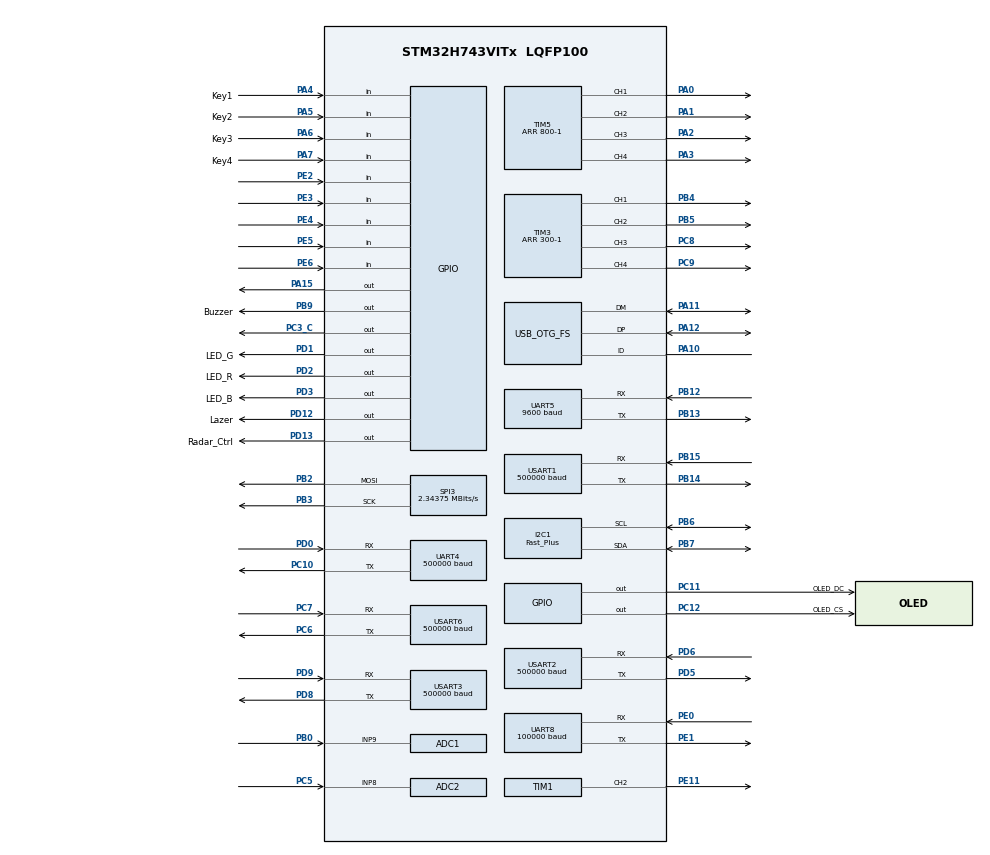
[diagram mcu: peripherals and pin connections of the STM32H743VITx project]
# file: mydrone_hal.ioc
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ADC1.Channel-3\#ChannelRegularConversion=ADC_CHANNEL_9
ADC1.ClockPrescaler=ADC_CLOCK_ASYNC_DIV4
ADC1.ContinuousConvMode=ENABLE
ADC1.ConversionDataManagement=ADC_CONVERSIONDATA_DMA_CIRCULAR
ADC1.NbrOfConversionFlag=1
ADC1.OffsetNumber-3\#ChannelRegularConversion=ADC_OFFSET_NONE
ADC1.OffsetSignedSaturation-3\#ChannelRegularConversion=DISABLE
ADC1.Overrun=ADC_OVR_DATA_OVERWRITTEN
ADC1.Rank-3\#ChannelRegularConversion=1
ADC1.Resolution=ADC_RESOLUTION_16B
ADC1.SamplingTime-3\#ChannelRegularConversion=ADC_SAMPLETIME_810CYCLES_5
ADC1.master=1
ADC2.Channel-1\#ChannelRegularConversion=ADC_CHANNEL_8
ADC2.ClockPrescaler=ADC_CLOCK_ASYNC_DIV4
ADC2.ContinuousConvMode=ENABLE
ADC2.ConversionDataManagement=ADC_CONVERSIONDATA_DMA_CIRCULAR
ADC2.NbrOfConversionFlag=1
ADC2.OffsetNumber-1\#ChannelRegularConversion=ADC_OFFSET_NONE
ADC2.OffsetSignedSaturation-1\#ChannelRegularConversion=DISABLE
ADC2.Overrun=ADC_OVR_DATA_OVERWRITTEN
ADC2.Rank-1\#ChannelRegularConversion=1
ADC2.Resolution=ADC_RESOLUTION_16B
ADC2.SamplingTime-1\#ChannelRegularConversion=ADC_SAMPLETIME_810CYCLES_5
CORTEX_M7.AccessPermission_S-Cortex_Memory_Protection_Unit_Region1_Settings_S=MPU_REGION_FULL_ACCESS
CORTEX_M7.AccessPermission_Spec=MPU_REGION_FULL_ACCESS
CORTEX_M7.BaseAddress_S-Cortex_Memory_Protection_Unit_Region1_Settings_S=0x24000000
CORTEX_M7.BaseAddress_Spec=0x24000000
CORTEX_M7.CPU_DCache=Enabled
CORTEX_M7.CPU_ICache=Enabled
CORTEX_M7.DisableExec_S-Cortex_Memory_Protection_Unit_Region1_Settings_S=MPU_INSTRUCTION_ACCESS_DISABLE
CORTEX_M7.DisableExec_Spec=MPU_INSTRUCTION_ACCESS_DISABLE
CORTEX_M7.Enable_S-Cortex_Memory_Protection_Unit_Region1_Settings_S=MPU_REGION_ENABLE
CORTEX_M7.Enable_Spec=MPU_REGION_ENABLE
CORTEX_M7.IsBufferable_S-Cortex_Memory_Protection_Unit_Region1_Settings_S=MPU_ACCESS_BUFFERABLE
CORTEX_M7.IsBufferable_Spec=MPU_ACCESS_NOT_BUFFERABLE
CORTEX_M7.IsCacheable_S-Cortex_Memory_Protection_Unit_Region1_Settings_S=MPU_ACCESS_CACHEABLE
CORTEX_M7.IsCacheable_Spec=MPU_ACCESS_NOT_CACHEABLE
CORTEX_M7.IsShareable_Spec=MPU_ACCESS_NOT_SHAREABLE
CORTEX_M7.Size_S-Cortex_Memory_Protection_Unit_Region1_Settings_S=MPU_REGION_SIZE_512KB
CORTEX_M7.Size_Spec=MPU_REGION_SIZE_4KB
CORTEX_M7.SubRegionDisable_S-Cortex_Memory_Protection_Unit_Region1_Settings_S=0x01
CORTEX_M7.SubRegionDisable_Spec=0x00
CORTEX_M7.TypeExtField_S-Cortex_Memory_Protection_Unit_Region1_Settings_S=MPU_TEX_LEVEL1
CORTEX_M7.TypeExtField_Spec=MPU_TEX_LEVEL1
CORTEX_M7.default_mode_Activation=1
Dma.ADC1.8.Direction=DMA_PERIPH_TO_MEMORY
Dma.ADC1.8.EventEnable=DISABLE
Dma.ADC1.8.FIFOMode=DMA_FIFOMODE_DISABLE
Dma.ADC1.8.Instance=DMA2_Stream2
Dma.ADC1.8.MemDataAlignment=DMA_MDATAALIGN_HALFWORD
Dma.ADC1.8.MemInc=DMA_MINC_ENABLE
Dma.ADC1.8.Mode=DMA_CIRCULAR
Dma.ADC1.8.PeriphDataAlignment=DMA_PDATAALIGN_HALFWORD
Dma.ADC1.8.PeriphInc=DMA_PINC_DISABLE
Dma.ADC1.8.Polarity=HAL_DMAMUX_REQ_GEN_RISING
Dma.ADC1.8.Priority=DMA_PRIORITY_LOW
Dma.ADC1.8.RequestNumber=1
Dma.ADC1.8.SignalID=NONE
Dma.ADC1.8.SyncEnable=DISABLE
Dma.ADC1.8.SyncPolarity=HAL_DMAMUX_SYNC_NO_EVENT
Dma.ADC1.8.SyncRequestNumber=1
Dma.ADC1.8.SyncSignalID=NONE
Dma.ADC2.6.Direction=DMA_PERIPH_TO_MEMORY
Dma.ADC2.6.EventEnable=DISABLE
Dma.ADC2.6.FIFOMode=DMA_FIFOMODE_DISABLE
Dma.ADC2.6.Instance=DMA2_Stream1
Dma.ADC2.6.MemDataAlignment=DMA_MDATAALIGN_HALFWORD
Dma.ADC2.6.MemInc=DMA_MINC_ENABLE
Dma.ADC2.6.Mode=DMA_CIRCULAR
Dma.ADC2.6.PeriphDataAlignment=DMA_PDATAALIGN_HALFWORD
Dma.ADC2.6.PeriphInc=DMA_PINC_DISABLE
Dma.ADC2.6.Polarity=HAL_DMAMUX_REQ_GEN_RISING
Dma.ADC2.6.Priority=DMA_PRIORITY_LOW
Dma.ADC2.6.RequestNumber=1
Dma.ADC2.6.SignalID=NONE
Dma.ADC2.6.SyncEnable=DISABLE
Dma.ADC2.6.SyncPolarity=HAL_DMAMUX_SYNC_NO_EVENT
Dma.ADC2.6.SyncRequestNumber=1
Dma.ADC2.6.SyncSignalID=NONE
Dma.Request0=UART4_TX
Dma.Request1=UART4_RX
Dma.Request10=TIM3_CH2
Dma.Request11=TIM3_CH3
Dma.Request12=TIM3_CH4
Dma.Request13=USART6_TX
Dma.Request14=USART3_RX
Dma.Request15=USART1_TX
Dma.Request2=TIM5_CH1
Dma.Request3=TIM5_CH2
Dma.Request4=TIM5_CH3
Dma.Request5=TIM5_CH4
Dma.Request6=ADC2
Dma.Request7=USART2_RX
Dma.Request8=ADC1
Dma.Request9=TIM3_CH1
Dma.TIM3_CH1.9.Direction=DMA_MEMORY_TO_PERIPH
Dma.TIM3_CH1.9.EventEnable=DISABLE
Dma.TIM3_CH1.9.FIFOMode=DMA_FIFOMODE_DISABLE
Dma.TIM3_CH1.9.Instance=DMA2_Stream3
Dma.TIM3_CH1.9.MemDataAlignment=DMA_MDATAALIGN_HALFWORD
Dma.TIM3_CH1.9.MemInc=DMA_MINC_ENABLE
Dma.TIM3_CH1.9.Mode=DMA_NORMAL
Dma.TIM3_CH1.9.PeriphDataAlignment=DMA_PDATAALIGN_HALFWORD
Dma.TIM3_CH1.9.PeriphInc=DMA_PINC_DISABLE
Dma.TIM3_CH1.9.Polarity=HAL_DMAMUX_REQ_GEN_RISING
Dma.TIM3_CH1.9.Priority=DMA_PRIORITY_LOW
Dma.TIM3_CH1.9.RequestNumber=1
Dma.TIM3_CH1.9.SignalID=NONE
Dma.TIM3_CH1.9.SyncEnable=DISABLE
Dma.TIM3_CH1.9.SyncPolarity=HAL_DMAMUX_SYNC_NO_EVENT
Dma.TIM3_CH1.9.SyncRequestNumber=1
Dma.TIM3_CH1.9.SyncSignalID=NONE
Dma.TIM3_CH2.10.Direction=DMA_MEMORY_TO_PERIPH
Dma.TIM3_CH2.10.EventEnable=DISABLE
Dma.TIM3_CH2.10.FIFOMode=DMA_FIFOMODE_DISABLE
Dma.TIM3_CH2.10.Instance=DMA2_Stream4
Dma.TIM3_CH2.10.MemDataAlignment=DMA_MDATAALIGN_HALFWORD
Dma.TIM3_CH2.10.MemInc=DMA_MINC_ENABLE
Dma.TIM3_CH2.10.Mode=DMA_NORMAL
Dma.TIM3_CH2.10.PeriphDataAlignment=DMA_PDATAALIGN_HALFWORD
Dma.TIM3_CH2.10.PeriphInc=DMA_PINC_DISABLE
Dma.TIM3_CH2.10.Polarity=HAL_DMAMUX_REQ_GEN_RISING
Dma.TIM3_CH2.10.Priority=DMA_PRIORITY_LOW
Dma.TIM3_CH2.10.RequestNumber=1
Dma.TIM3_CH2.10.SignalID=NONE
Dma.TIM3_CH2.10.SyncEnable=DISABLE
Dma.TIM3_CH2.10.SyncPolarity=HAL_DMAMUX_SYNC_NO_EVENT
Dma.TIM3_CH2.10.SyncRequestNumber=1
Dma.TIM3_CH2.10.SyncSignalID=NONE
Dma.TIM3_CH3.11.Direction=DMA_MEMORY_TO_PERIPH
Dma.TIM3_CH3.11.EventEnable=DISABLE
Dma.TIM3_CH3.11.FIFOMode=DMA_FIFOMODE_DISABLE
Dma.TIM3_CH3.11.Instance=DMA2_Stream6
Dma.TIM3_CH3.11.MemDataAlignment=DMA_MDATAALIGN_HALFWORD
Dma.TIM3_CH3.11.MemInc=DMA_MINC_ENABLE
Dma.TIM3_CH3.11.Mode=DMA_NORMAL
Dma.TIM3_CH3.11.PeriphDataAlignment=DMA_PDATAALIGN_HALFWORD
Dma.TIM3_CH3.11.PeriphInc=DMA_PINC_DISABLE
Dma.TIM3_CH3.11.Polarity=HAL_DMAMUX_REQ_GEN_RISING
Dma.TIM3_CH3.11.Priority=DMA_PRIORITY_LOW
Dma.TIM3_CH3.11.RequestNumber=1
Dma.TIM3_CH3.11.SignalID=NONE
Dma.TIM3_CH3.11.SyncEnable=DISABLE
Dma.TIM3_CH3.11.SyncPolarity=HAL_DMAMUX_SYNC_NO_EVENT
Dma.TIM3_CH3.11.SyncRequestNumber=1
Dma.TIM3_CH3.11.SyncSignalID=NONE
Dma.TIM3_CH4.12.Direction=DMA_MEMORY_TO_PERIPH
Dma.TIM3_CH4.12.EventEnable=DISABLE
Dma.TIM3_CH4.12.FIFOMode=DMA_FIFOMODE_DISABLE
Dma.TIM3_CH4.12.Instance=DMA2_Stream7
Dma.TIM3_CH4.12.MemDataAlignment=DMA_MDATAALIGN_HALFWORD
Dma.TIM3_CH4.12.MemInc=DMA_MINC_ENABLE
Dma.TIM3_CH4.12.Mode=DMA_NORMAL
Dma.TIM3_CH4.12.PeriphDataAlignment=DMA_PDATAALIGN_HALFWORD
Dma.TIM3_CH4.12.PeriphInc=DMA_PINC_DISABLE
Dma.TIM3_CH4.12.Polarity=HAL_DMAMUX_REQ_GEN_RISING
Dma.TIM3_CH4.12.Priority=DMA_PRIORITY_LOW
Dma.TIM3_CH4.12.RequestNumber=1
Dma.TIM3_CH4.12.SignalID=NONE
Dma.TIM3_CH4.12.SyncEnable=DISABLE
Dma.TIM3_CH4.12.SyncPolarity=HAL_DMAMUX_SYNC_NO_EVENT
Dma.TIM3_CH4.12.SyncRequestNumber=1
Dma.TIM3_CH4.12.SyncSignalID=NONE
Dma.TIM5_CH1.2.Direction=DMA_MEMORY_TO_PERIPH
Dma.TIM5_CH1.2.EventEnable=DISABLE
Dma.TIM5_CH1.2.FIFOMode=DMA_FIFOMODE_DISABLE
Dma.TIM5_CH1.2.Instance=DMA1_Stream5
Dma.TIM5_CH1.2.MemDataAlignment=DMA_MDATAALIGN_WORD
Dma.TIM5_CH1.2.MemInc=DMA_MINC_ENABLE
Dma.TIM5_CH1.2.Mode=DMA_NORMAL
Dma.TIM5_CH1.2.PeriphDataAlignment=DMA_PDATAALIGN_WORD
Dma.TIM5_CH1.2.PeriphInc=DMA_PINC_DISABLE
Dma.TIM5_CH1.2.Polarity=HAL_DMAMUX_REQ_GEN_RISING
Dma.TIM5_CH1.2.Priority=DMA_PRIORITY_HIGH
Dma.TIM5_CH1.2.RequestNumber=1
Dma.TIM5_CH1.2.SignalID=NONE
Dma.TIM5_CH1.2.SyncEnable=DISABLE
Dma.TIM5_CH1.2.SyncPolarity=HAL_DMAMUX_SYNC_NO_EVENT
Dma.TIM5_CH1.2.SyncRequestNumber=1
Dma.TIM5_CH1.2.SyncSignalID=NONE
Dma.TIM5_CH2.3.Direction=DMA_MEMORY_TO_PERIPH
Dma.TIM5_CH2.3.EventEnable=DISABLE
Dma.TIM5_CH2.3.FIFOMode=DMA_FIFOMODE_DISABLE
Dma.TIM5_CH2.3.Instance=DMA1_Stream6
Dma.TIM5_CH2.3.MemDataAlignment=DMA_MDATAALIGN_WORD
Dma.TIM5_CH2.3.MemInc=DMA_MINC_ENABLE
Dma.TIM5_CH2.3.Mode=DMA_NORMAL
Dma.TIM5_CH2.3.PeriphDataAlignment=DMA_PDATAALIGN_WORD
Dma.TIM5_CH2.3.PeriphInc=DMA_PINC_DISABLE
Dma.TIM5_CH2.3.Polarity=HAL_DMAMUX_REQ_GEN_RISING
Dma.TIM5_CH2.3.Priority=DMA_PRIORITY_HIGH
Dma.TIM5_CH2.3.RequestNumber=1
Dma.TIM5_CH2.3.SignalID=NONE
Dma.TIM5_CH2.3.SyncEnable=DISABLE
Dma.TIM5_CH2.3.SyncPolarity=HAL_DMAMUX_SYNC_NO_EVENT
Dma.TIM5_CH2.3.SyncRequestNumber=1
Dma.TIM5_CH2.3.SyncSignalID=NONE
Dma.TIM5_CH3.4.Direction=DMA_MEMORY_TO_PERIPH
Dma.TIM5_CH3.4.EventEnable=DISABLE
Dma.TIM5_CH3.4.FIFOMode=DMA_FIFOMODE_DISABLE
Dma.TIM5_CH3.4.Instance=DMA1_Stream7
Dma.TIM5_CH3.4.MemDataAlignment=DMA_MDATAALIGN_WORD
Dma.TIM5_CH3.4.MemInc=DMA_MINC_ENABLE
Dma.TIM5_CH3.4.Mode=DMA_NORMAL
Dma.TIM5_CH3.4.PeriphDataAlignment=DMA_PDATAALIGN_WORD
Dma.TIM5_CH3.4.PeriphInc=DMA_PINC_DISABLE
Dma.TIM5_CH3.4.Polarity=HAL_DMAMUX_REQ_GEN_RISING
Dma.TIM5_CH3.4.Priority=DMA_PRIORITY_HIGH
Dma.TIM5_CH3.4.RequestNumber=1
Dma.TIM5_CH3.4.SignalID=NONE
Dma.TIM5_CH3.4.SyncEnable=DISABLE
Dma.TIM5_CH3.4.SyncPolarity=HAL_DMAMUX_SYNC_NO_EVENT
Dma.TIM5_CH3.4.SyncRequestNumber=1
Dma.TIM5_CH3.4.SyncSignalID=NONE
Dma.TIM5_CH4.5.Direction=DMA_MEMORY_TO_PERIPH
Dma.TIM5_CH4.5.EventEnable=DISABLE
Dma.TIM5_CH4.5.FIFOMode=DMA_FIFOMODE_DISABLE
Dma.TIM5_CH4.5.Instance=DMA2_Stream0
Dma.TIM5_CH4.5.MemDataAlignment=DMA_MDATAALIGN_WORD
Dma.TIM5_CH4.5.MemInc=DMA_MINC_ENABLE
Dma.TIM5_CH4.5.Mode=DMA_NORMAL
Dma.TIM5_CH4.5.PeriphDataAlignment=DMA_PDATAALIGN_WORD
Dma.TIM5_CH4.5.PeriphInc=DMA_PINC_DISABLE
Dma.TIM5_CH4.5.Polarity=HAL_DMAMUX_REQ_GEN_RISING
Dma.TIM5_CH4.5.Priority=DMA_PRIORITY_HIGH
Dma.TIM5_CH4.5.RequestNumber=1
Dma.TIM5_CH4.5.SignalID=NONE
Dma.TIM5_CH4.5.SyncEnable=DISABLE
Dma.TIM5_CH4.5.SyncPolarity=HAL_DMAMUX_SYNC_NO_EVENT
Dma.TIM5_CH4.5.SyncRequestNumber=1
Dma.TIM5_CH4.5.SyncSignalID=NONE
Dma.UART4_RX.1.Direction=DMA_PERIPH_TO_MEMORY
Dma.UART4_RX.1.EventEnable=DISABLE
Dma.UART4_RX.1.FIFOMode=DMA_FIFOMODE_DISABLE
Dma.UART4_RX.1.Instance=DMA1_Stream1
Dma.UART4_RX.1.MemDataAlignment=DMA_MDATAALIGN_BYTE
Dma.UART4_RX.1.MemInc=DMA_MINC_ENABLE
Dma.UART4_RX.1.Mode=DMA_CIRCULAR
Dma.UART4_RX.1.PeriphDataAlignment=DMA_PDATAALIGN_BYTE
Dma.UART4_RX.1.PeriphInc=DMA_PINC_DISABLE
Dma.UART4_RX.1.Polarity=HAL_DMAMUX_REQ_GEN_RISING
Dma.UART4_RX.1.Priority=DMA_PRIORITY_LOW
Dma.UART4_RX.1.RequestNumber=1
Dma.UART4_RX.1.SignalID=NONE
Dma.UART4_RX.1.SyncEnable=DISABLE
Dma.UART4_RX.1.SyncPolarity=HAL_DMAMUX_SYNC_NO_EVENT
Dma.UART4_RX.1.SyncRequestNumber=1
Dma.UART4_RX.1.SyncSignalID=NONE
Dma.UART4_TX.0.Direction=DMA_MEMORY_TO_PERIPH
Dma.UART4_TX.0.EventEnable=DISABLE
Dma.UART4_TX.0.FIFOMode=DMA_FIFOMODE_DISABLE
Dma.UART4_TX.0.Instance=DMA1_Stream0
Dma.UART4_TX.0.MemDataAlignment=DMA_MDATAALIGN_BYTE
Dma.UART4_TX.0.MemInc=DMA_MINC_ENABLE
Dma.UART4_TX.0.Mode=DMA_NORMAL
Dma.UART4_TX.0.PeriphDataAlignment=DMA_PDATAALIGN_BYTE
Dma.UART4_TX.0.PeriphInc=DMA_PINC_DISABLE
Dma.UART4_TX.0.Polarity=HAL_DMAMUX_REQ_GEN_RISING
Dma.UART4_TX.0.Priority=DMA_PRIORITY_LOW
Dma.UART4_TX.0.RequestNumber=1
Dma.UART4_TX.0.SignalID=NONE
Dma.UART4_TX.0.SyncEnable=DISABLE
Dma.UART4_TX.0.SyncPolarity=HAL_DMAMUX_SYNC_NO_EVENT
Dma.UART4_TX.0.SyncRequestNumber=1
Dma.UART4_TX.0.SyncSignalID=NONE
Dma.USART1_TX.15.Direction=DMA_MEMORY_TO_PERIPH
Dma.USART1_TX.15.EventEnable=DISABLE
Dma.USART1_TX.15.FIFOMode=DMA_FIFOMODE_DISABLE
Dma.USART1_TX.15.Instance=DMA1_Stream3
Dma.USART1_TX.15.MemDataAlignment=DMA_MDATAALIGN_BYTE
Dma.USART1_TX.15.MemInc=DMA_MINC_ENABLE
Dma.USART1_TX.15.Mode=DMA_NORMAL
Dma.USART1_TX.15.PeriphDataAlignment=DMA_PDATAALIGN_BYTE
Dma.USART1_TX.15.PeriphInc=DMA_PINC_DISABLE
Dma.USART1_TX.15.Polarity=HAL_DMAMUX_REQ_GEN_RISING
Dma.USART1_TX.15.Priority=DMA_PRIORITY_LOW
Dma.USART1_TX.15.RequestNumber=1
Dma.USART1_TX.15.SignalID=NONE
Dma.USART1_TX.15.SyncEnable=DISABLE
Dma.USART1_TX.15.SyncPolarity=HAL_DMAMUX_SYNC_NO_EVENT
Dma.USART1_TX.15.SyncRequestNumber=1
Dma.USART1_TX.15.SyncSignalID=NONE
Dma.USART2_RX.7.Direction=DMA_PERIPH_TO_MEMORY
Dma.USART2_RX.7.EventEnable=DISABLE
Dma.USART2_RX.7.FIFOMode=DMA_FIFOMODE_DISABLE
Dma.USART2_RX.7.Instance=DMA1_Stream2
Dma.USART2_RX.7.MemDataAlignment=DMA_MDATAALIGN_BYTE
Dma.USART2_RX.7.MemInc=DMA_MINC_ENABLE
Dma.USART2_RX.7.Mode=DMA_CIRCULAR
Dma.USART2_RX.7.PeriphDataAlignment=DMA_PDATAALIGN_BYTE
Dma.USART2_RX.7.PeriphInc=DMA_PINC_DISABLE
Dma.USART2_RX.7.Polarity=HAL_DMAMUX_REQ_GEN_RISING
Dma.USART2_RX.7.Priority=DMA_PRIORITY_LOW
Dma.USART2_RX.7.RequestNumber=1
Dma.USART2_RX.7.SignalID=NONE
Dma.USART2_RX.7.SyncEnable=DISABLE
Dma.USART2_RX.7.SyncPolarity=HAL_DMAMUX_SYNC_NO_EVENT
Dma.USART2_RX.7.SyncRequestNumber=1
Dma.USART2_RX.7.SyncSignalID=NONE
Dma.USART3_RX.14.Direction=DMA_PERIPH_TO_MEMORY
Dma.USART3_RX.14.EventEnable=DISABLE
Dma.USART3_RX.14.FIFOMode=DMA_FIFOMODE_DISABLE
Dma.USART3_RX.14.Instance=DMA2_Stream5
Dma.USART3_RX.14.MemDataAlignment=DMA_MDATAALIGN_BYTE
Dma.USART3_RX.14.MemInc=DMA_MINC_ENABLE
Dma.USART3_RX.14.Mode=DMA_CIRCULAR
Dma.USART3_RX.14.PeriphDataAlignment=DMA_PDATAALIGN_BYTE
Dma.USART3_RX.14.PeriphInc=DMA_PINC_DISABLE
Dma.USART3_RX.14.Polarity=HAL_DMAMUX_REQ_GEN_RISING
Dma.USART3_RX.14.Priority=DMA_PRIORITY_LOW
Dma.USART3_RX.14.RequestNumber=1
Dma.USART3_RX.14.SignalID=NONE
Dma.USART3_RX.14.SyncEnable=DISABLE
Dma.USART3_RX.14.SyncPolarity=HAL_DMAMUX_SYNC_NO_EVENT
Dma.USART3_RX.14.SyncRequestNumber=1
Dma.USART3_RX.14.SyncSignalID=NONE
Dma.USART6_TX.13.Direction=DMA_MEMORY_TO_PERIPH
Dma.USART6_TX.13.EventEnable=DISABLE
Dma.USART6_TX.13.FIFOMode=DMA_FIFOMODE_DISABLE
Dma.USART6_TX.13.Instance=DMA1_Stream4
Dma.USART6_TX.13.MemDataAlignment=DMA_MDATAALIGN_BYTE
Dma.USART6_TX.13.MemInc=DMA_MINC_ENABLE
Dma.USART6_TX.13.Mode=DMA_NORMAL
Dma.USART6_TX.13.PeriphDataAlignment=DMA_PDATAALIGN_BYTE
Dma.USART6_TX.13.PeriphInc=DMA_PINC_DISABLE
Dma.USART6_TX.13.Polarity=HAL_DMAMUX_REQ_GEN_RISING
Dma.USART6_TX.13.Priority=DMA_PRIORITY_LOW
Dma.USART6_TX.13.RequestNumber=1
Dma.USART6_TX.13.SignalID=NONE
Dma.USART6_TX.13.SyncEnable=DISABLE
Dma.USART6_TX.13.SyncPolarity=HAL_DMAMUX_SYNC_NO_EVENT
Dma.USART6_TX.13.SyncRequestNumber=1
Dma.USART6_TX.13.SyncSignalID=NONE
FREERTOS.Tasks01=task_1ms_name,40,1024,task_1ms,As weak,NULL,Dynamic,NULL,NULL;task_tx_event,32,512,task_tx,As weak,NULL,Dynamic,NULL,NULL;task_rx_event,32,512,task_rx,As weak,NULL,Dynamic,NULL,NULL;task_ano_send_e,30,512,task_ano_send,As weak,NULL,Dynamic,NULL,NULL;task_event_name,31,256,task_event,As weak,NULL,Dynamic,NULL,NULL;task_timer_even,33,128,task_timer_event,As weak,NULL,Dynamic,NULL,NULL;task_10ms_name,29,512,task_10ms,As weak,NULL,Dynamic,NULL,NULL
FREERTOS.configENABLE_FPU=0
FREERTOS.configGENERATE_RUN_TIME_STATS=1
FREERTOS.configTOTAL_HEAP_SIZE=32768
FREERTOS.configUSE_STATS_FORMATTING_FUNCTIONS=1
I2C1.I2C_Speed_Mode=I2C_Fast_Plus
I2C1.Timing=0x0050174F
Mcu.Family=STM32H7
Mcu.Name=STM32H743VITx
Mcu.Package=LQFP100
NVIC.DMA1_Stream0_IRQn=true\:5\:0\:false\:false\:true\:true\:false\:true\:true
NVIC.DMA1_Stream1_IRQn=true\:5\:0\:false\:false\:true\:true\:false\:true\:true
NVIC.DMA1_Stream2_IRQn=true\:5\:0\:false\:false\:true\:true\:false\:true\:true
NVIC.DMA1_Stream3_IRQn=true\:5\:0\:false\:false\:true\:true\:false\:true\:true
NVIC.DMA1_Stream4_IRQn=true\:5\:0\:false\:false\:true\:true\:false\:true\:true
NVIC.DMA1_Stream5_IRQn=true\:5\:0\:false\:false\:true\:true\:false\:true\:true
NVIC.DMA1_Stream6_IRQn=true\:5\:0\:false\:false\:true\:true\:false\:true\:true
NVIC.DMA1_Stream7_IRQn=true\:5\:0\:false\:false\:true\:true\:false\:true\:true
NVIC.DMA2_Stream0_IRQn=true\:5\:0\:false\:false\:true\:true\:false\:true\:true
NVIC.DMA2_Stream1_IRQn=true\:5\:0\:false\:false\:true\:true\:false\:true\:true
NVIC.DMA2_Stream2_IRQn=true\:5\:0\:false\:false\:true\:true\:false\:true\:true
NVIC.DMA2_Stream3_IRQn=true\:5\:0\:false\:false\:true\:true\:false\:true\:true
NVIC.DMA2_Stream4_IRQn=true\:5\:0\:false\:false\:true\:true\:false\:true\:true
NVIC.DMA2_Stream5_IRQn=true\:5\:0\:false\:false\:true\:true\:false\:true\:true
NVIC.DMA2_Stream6_IRQn=true\:5\:0\:false\:false\:true\:true\:false\:true\:true
NVIC.DMA2_Stream7_IRQn=true\:5\:0\:false\:false\:true\:true\:false\:true\:true
NVIC.I2C1_ER_IRQn=true\:5\:0\:false\:false\:true\:true\:true\:true\:true
NVIC.I2C1_EV_IRQn=true\:5\:0\:false\:false\:true\:true\:true\:true\:true
NVIC.PriorityGroup=NVIC_PRIORITYGROUP_4
NVIC.SPI3_IRQn=true\:5\:0\:false\:false\:true\:true\:true\:true\:true
NVIC.TIM16_IRQn=true\:5\:0\:false\:false\:true\:true\:true\:true\:true
NVIC.TIM17_IRQn=true\:15\:0\:true\:false\:true\:false\:false\:true\:true
NVIC.TIM3_IRQn=true\:5\:0\:false\:false\:true\:true\:true\:true\:true
NVIC.TIM8_TRG_COM_TIM14_IRQn=true\:5\:0\:false\:false\:true\:true\:true\:true\:true
NVIC.TimeBase=TIM17_IRQn
NVIC.TimeBaseIP=TIM17
NVIC.UART4_IRQn=true\:5\:0\:false\:false\:true\:true\:false\:true\:true
NVIC.UART5_IRQn=true\:5\:0\:false\:false\:true\:true\:true\:true\:true
NVIC.UART8_IRQn=true\:5\:0\:false\:false\:true\:true\:false\:true\:true
NVIC.USART1_IRQn=true\:5\:0\:false\:false\:true\:true\:true\:true\:true
NVIC.USART2_IRQn=true\:5\:0\:false\:false\:true\:true\:false\:true\:true
NVIC.USART3_IRQn=true\:5\:0\:false\:false\:true\:true\:true\:true\:true
NVIC.USART6_IRQn=true\:5\:0\:false\:false\:true\:true\:true\:true\:true
PA0.GPIO_PuPd=GPIO_PULLDOWN
PA0.Signal=S_TIM5_CH1
PA1.GPIO_PuPd=GPIO_PULLDOWN
PA1.Signal=S_TIM5_CH2
PA10.Mode=OTG/Dual_Role_Device
PA10.Signal=USB_OTG_FS_ID
PA11.Mode=OTG/Dual_Role_Device
PA11.Signal=USB_OTG_FS_DM
PA12.Mode=OTG/Dual_Role_Device
PA12.Signal=USB_OTG_FS_DP
PA13\ (JTMS/SWDIO).Mode=Serial_Wire
PA13\ (JTMS/SWDIO).Signal=DEBUG_JTMS-SWDIO
PA14\ (JTCK/SWCLK).Mode=Serial_Wire
PA14\ (JTCK/SWCLK).Signal=DEBUG_JTCK-SWCLK
PA15\ (JTDI).Signal=GPIO_Output
PA2.GPIO_PuPd=GPIO_PULLDOWN
PA2.Signal=S_TIM5_CH3
PA3.GPIO_PuPd=GPIO_PULLDOWN
PA3.Signal=S_TIM5_CH4
PA4.GPIO_Label=Key1
PA4.GPIO_PuPd=GPIO_PULLDOWN
PA4.Signal=GPIO_Input
PA5.GPIO_Label=Key2
PA5.GPIO_PuPd=GPIO_PULLUP
PA5.Signal=GPIO_Input
PA6.GPIO_Label=Key3
PA6.GPIO_PuPd=GPIO_PULLDOWN
PA6.Signal=GPIO_Input
PA7.GPIO_Label=Key4
PA7.GPIO_PuPd=GPIO_PULLDOWN
PA7.Signal=GPIO_Input
PB0.Signal=ADCx_INP9
PB12.Mode=Asynchronous
PB12.Signal=UART5_RX
PB13.Mode=Asynchronous
PB13.Signal=UART5_TX
PB14.Mode=Asynchronous
PB14.Signal=USART1_TX
PB15.Mode=Asynchronous
PB15.Signal=USART1_RX
PB2.Mode=TX_Only_Simplex_Unidirect_Master
PB2.Signal=SPI3_MOSI
PB3\ (JTDO/TRACESWO).Mode=TX_Only_Simplex_Unidirect_Master
PB3\ (JTDO/TRACESWO).Signal=SPI3_SCK
PB4\ (NJTRST).GPIO_PuPd=GPIO_PULLDOWN
PB4\ (NJTRST).Signal=S_TIM3_CH1
PB5.GPIO_PuPd=GPIO_PULLDOWN
PB5.Signal=S_TIM3_CH2
PB6.Mode=I2C
PB6.Signal=I2C1_SCL
PB7.Mode=I2C
PB7.Signal=I2C1_SDA
PB9.GPIO_Label=Buzzer
PB9.Signal=GPIO_Output
PC10.Mode=Asynchronous
PC10.Signal=UART4_TX
PC11.GPIO_Label=OLED_DC
PC11.PinState=GPIO_PIN_SET
PC11.Signal=GPIO_Output
PC12.GPIO_Label=OLED_CS
PC12.PinState=GPIO_PIN_SET
PC12.Signal=GPIO_Output
PC3_C.GPIO_Speed=GPIO_SPEED_FREQ_VERY_HIGH
PC3_C.Signal=GPIO_Output
PC5.Signal=ADCx_INP8
PC6.Mode=Asynchronous
PC6.Signal=USART6_TX
PC7.Mode=Asynchronous
PC7.Signal=USART6_RX
PC8.GPIO_PuPd=GPIO_PULLDOWN
PC8.Signal=S_TIM3_CH3
PC9.GPIO_PuPd=GPIO_PULLDOWN
PC9.Signal=S_TIM3_CH4
PD0.Mode=Asynchronous
PD0.Signal=UART4_RX
PD1.GPIO_Label=LED_G
PD1.Signal=GPIO_Output
PD12.GPIO_Label=Lazer
PD12.Signal=GPIO_Output
PD13.GPIO_Label=Radar_Ctrl
PD13.Signal=GPIO_Output
PD2.GPIO_Label=LED_R
PD2.Signal=GPIO_Output
PD3.GPIO_Label=LED_B
PD3.Signal=GPIO_Output
PD5.Mode=Asynchronous
PD5.Signal=USART2_TX
PD6.Mode=Asynchronous
PD6.Signal=USART2_RX
PD8.Mode=Asynchronous
PD8.Signal=USART3_TX
PD9.Mode=Asynchronous
PD9.Signal=USART3_RX
PE0.Mode=Asynchronous
PE0.Signal=UART8_RX
PE1.Mode=Asynchronous
PE1.Signal=UART8_TX
PE11.Signal=S_TIM1_CH2
PE2.Signal=GPIO_Input
PE3.Signal=GPIO_Input
PE4.Signal=GPIO_Input
PE5.GPIO_Mode=GPIO_MODE_INPUT
PE5.Signal=GPIO_Input
PE6.GPIO_PuPd=GPIO_NOPULL
PE6.Signal=GPIO_Input
PH0-OSC_IN\ (PH0).Mode=HSE-External-Oscillator
PH0-OSC_IN\ (PH0).Signal=RCC_OSC_IN
PH1-OSC_OUT\ (PH1).Mode=HSE-External-Oscillator
PH1-OSC_OUT\ (PH1).Signal=RCC_OSC_OUT
ProjectManager.HeapSize=0x1000
ProjectManager.StackSize=0x2000
ProjectManager.TargetToolchain=MDK-ARM V5.32
RCC.ADCFreq_Value=75000000
RCC.APB1Freq_Value=120000000
RCC.APB2Freq_Value=120000000
RCC.APB3Freq_Value=120000000
RCC.APB4Freq_Value=120000000
RCC.CortexFreq_Value=480000000
RCC.D1PPRE=RCC_APB3_DIV2
RCC.D2PPRE1=RCC_APB1_DIV2
RCC.D2PPRE2=RCC_APB2_DIV2
RCC.D3PPRE=RCC_APB4_DIV2
RCC.DIVM1=4
RCC.DIVM2=4
RCC.DIVM3=1
RCC.DIVN1=60
RCC.DIVN2=9
RCC.DIVP3=1
RCC.DIVQ3=1
RCC.DIVR3=1
RCC.HCLKFreq_Value=240000000
RCC.HPRE=RCC_HCLK_DIV2
RCC.HSE_VALUE=8000000
RCC.PLL2FRACN=3072
RCC.PLL3FRACN=0
RCC.PLL3_VCI_Range-AdvancedSettings=RCC_PLL3VCIRANGE_3
RCC.PLLFRACN=0
RCC.SPI123CLockSelection=RCC_SPI123CLKSOURCE_PLL2
RCC.SYSCLKFreq_VALUE=480000000
RCC.SYSCLKSource=RCC_SYSCLKSOURCE_PLLCLK
RCC.USBCLockSelection=RCC_USBCLKSOURCE_HSI48
RCC.USBFreq_Value=48000000
SH.ADCx_INP8.0=ADC2_INP8,IN8-Single-Ended
SH.ADCx_INP9.0=ADC1_INP9,IN9-Single-Ended
SH.S_TIM1_CH2.0=TIM1_CH2,PWM Generation2 CH2
SH.S_TIM3_CH1.0=TIM3_CH1,PWM Generation1 CH1
SH.S_TIM3_CH2.0=TIM3_CH2,PWM Generation2 CH2
SH.S_TIM3_CH3.0=TIM3_CH3,PWM Generation3 CH3
SH.S_TIM3_CH4.0=TIM3_CH4,PWM Generation4 CH4
SH.S_TIM5_CH1.0=TIM5_CH1,PWM Generation1 CH1
SH.S_TIM5_CH2.0=TIM5_CH2,PWM Generation2 CH2
SH.S_TIM5_CH3.0=TIM5_CH3,PWM Generation3 CH3
SH.S_TIM5_CH4.0=TIM5_CH4,PWM Generation4 CH4
SPI3.BaudRatePrescaler=SPI_BAUDRATEPRESCALER_32
SPI3.CalculateBaudRate=2.34375 MBits/s
SPI3.DataSize=SPI_DATASIZE_8BIT
SPI3.Direction=SPI_DIRECTION_2LINES_TXONLY
SPI3.IOSwap=SPI_IO_SWAP_DISABLE
SPI3.Mode=SPI_MODE_MASTER
SPI3.VirtualType=VM_MASTER
TIM1.Channel-PWM\ Generation2\ CH2=TIM_CHANNEL_2
TIM1.Channel-PWM\ Generation5\ No\ Output=TIM_CHANNEL_5
TIM1.Period=20000-1
TIM1.Prescaler=240-1
TIM1.Pulse-PWM\ Generation2\ CH2=0
TIM14.Period=50-1
TIM14.Prescaler=240-1
TIM16.Period=40-1
TIM16.Prescaler=6000-1
TIM3.Channel-PWM\ Generation1\ CH1=TIM_CHANNEL_1
TIM3.Channel-PWM\ Generation2\ CH2=TIM_CHANNEL_2
TIM3.Channel-PWM\ Generation3\ CH3=TIM_CHANNEL_3
TIM3.Channel-PWM\ Generation4\ CH4=TIM_CHANNEL_4
TIM3.Period=300-1
TIM5.Channel-PWM\ Generation1\ CH1=TIM_CHANNEL_1
TIM5.Channel-PWM\ Generation2\ CH2=TIM_CHANNEL_2
TIM5.Channel-PWM\ Generation3\ CH3=TIM_CHANNEL_3
TIM5.Channel-PWM\ Generation4\ CH4=TIM_CHANNEL_4
TIM5.Period=800-1
UART4.AutoBaudRateEnableParam=UART_ADVFEATURE_AUTOBAUDRATE_DISABLE
UART4.BaudRate=500000
UART4.FIFOMode=FIFOMODE_DISABLE
UART4.SwapParam=UART_ADVFEATURE_SWAP_ENABLE
UART5.BaudRate=9600
UART8.BaudRate=100000
UART8.Mode=MODE_RX
UART8.Parity=PARITY_EVEN
UART8.RxPinLevelInvertParam=UART_ADVFEATURE_RXINV_ENABLE
UART8.StopBits=UART_STOPBITS_2
UART8.SwapParam=UART_ADVFEATURE_SWAP_ENABLE
UART8.WordLength=WORDLENGTH_9B
USART1.BaudRate=500000
USART1.VirtualMode-Asynchronous=VM_ASYNC
USART2.BaudRate=500000
USART2.VirtualMode-Asynchronous=VM_ASYNC
USART3.BaudRate=500000
USART3.VirtualMode-Asynchronous=VM_ASYNC
USART6.BaudRate=500000
USART6.VirtualMode=VM_ASYNC
VP_FREERTOS_VS_CMSIS_V2.Mode=CMSIS_V2
VP_MEMORYMAP_VS_MEMORYMAP.Mode=CurAppReg
VP_SYS_VS_tim17.Mode=TIM17
VP_TIM14_VS_ClockSourceINT.Mode=Enable_Timer
VP_TIM16_VS_ClockSourceINT.Mode=Enable_Timer
VP_TIM1_VS_ClockSourceINT.Mode=Internal
VP_TIM1_VS_no_output5.Mode=PWM Generation5 No Output
VP_TIM3_VS_ClockSourceINT.Mode=Internal
VP_TIM4_VS_ClockSourceINT.Mode=Internal
board=custom

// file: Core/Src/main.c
/* USER CODE BEGIN Header */
/**
  ******************************************************************************
  * @file           : main.c
  * @brief          : Main program body
  ******************************************************************************
  * @attention
  *
  * Copyright (c) 2026 STMicroelectronics.
  * All rights reserved.
  *
  * This software is licensed under terms that can be found in the LICENSE file
  * in the root directory of this software component.
  * If no LICENSE file comes with this software, it is provided AS-IS.
  *
  ******************************************************************************
  */
/* USER CODE END Header */
#include "main.h"
#include "cmsis_os.h"
#include "adc.h"
#include "dma.h"
#include "i2c.h"
#include "spi.h"
#include "tim.h"
#include "usart.h"
#include "usb_otg.h"
#include "gpio.h"

void SystemClock_Config(void);
void PeriphCommonClock_Config(void);
static void MPU_Config(void);
void MX_FREERTOS_Init(void);

int main(void)
{

  /* MPU Configuration--------------------------------------------------------*/
  MPU_Config();

  /* Enable the CPU Cache */

  /* Enable I-Cache---------------------------------------------------------*/
  SCB_EnableICache();

  /* Enable D-Cache---------------------------------------------------------*/
  SCB_EnableDCache();

  /* MCU Configuration--------------------------------------------------------*/

  /* Reset of all peripherals, Initializes the Flash interface and the Systick. */
  HAL_Init();

  /* Configure the system clock */
  SystemClock_Config();

  /* Configure the peripherals common clocks */
  PeriphCommonClock_Config();

  /* Initialize all configured peripherals */
  MX_GPIO_Init();
  MX_DMA_Init();
  MX_UART4_Init();
  MX_UART8_Init();
  MX_TIM5_Init();
  MX_USB_OTG_FS_USB_Init();
  MX_USART2_UART_Init();
  MX_TIM4_Init();
  MX_ADC2_Init();
  MX_TIM3_Init();
  MX_ADC1_Init();
  MX_USART1_UART_Init();
  MX_I2C1_Init();
  MX_USART6_UART_Init();
  MX_TIM1_Init();
  MX_TIM16_Init();
  MX_SPI3_Init();
  MX_USART3_UART_Init();
  MX_TIM14_Init();
  MX_UART5_Init();

  /* Init scheduler */
  osKernelInitialize();  /* Call init function for freertos objects (in cmsis_os2.c) */
  MX_FREERTOS_Init();

  /* Start scheduler */
  osKernelStart();

  /* We should never get here as control is now taken by the scheduler */

  /* Infinite loop */
  while (1)
  {

  }
}

void SystemClock_Config(void)
{
  RCC_OscInitTypeDef RCC_OscInitStruct = {0};
  RCC_ClkInitTypeDef RCC_ClkInitStruct = {0};

  /** Supply configuration update enable
  */
  HAL_PWREx_ConfigSupply(PWR_LDO_SUPPLY);

  /** Configure the main internal regulator output voltage
  */
  __HAL_PWR_VOLTAGESCALING_CONFIG(PWR_REGULATOR_VOLTAGE_SCALE0);

  while(!__HAL_PWR_GET_FLAG(PWR_FLAG_VOSRDY)) {}

  /** Initializes the RCC Oscillators according to the specified parameters
  * in the RCC_OscInitTypeDef structure.
  */
  RCC_OscInitStruct.OscillatorType = RCC_OSCILLATORTYPE_HSI48|RCC_OSCILLATORTYPE_HSI;
  RCC_OscInitStruct.HSIState = RCC_HSI_DIV1;
  RCC_OscInitStruct.HSICalibrationValue = RCC_HSICALIBRATION_DEFAULT;
  RCC_OscInitStruct.HSI48State = RCC_HSI48_ON;
  RCC_OscInitStruct.PLL.PLLState = RCC_PLL_ON;
  RCC_OscInitStruct.PLL.PLLSource = RCC_PLLSOURCE_HSI;
  RCC_OscInitStruct.PLL.PLLM = 4;
  RCC_OscInitStruct.PLL.PLLN = 60;
  RCC_OscInitStruct.PLL.PLLP = 2;
  RCC_OscInitStruct.PLL.PLLQ = 2;
  RCC_OscInitStruct.PLL.PLLR = 2;
  RCC_OscInitStruct.PLL.PLLRGE = RCC_PLL1VCIRANGE_3;
  RCC_OscInitStruct.PLL.PLLVCOSEL = RCC_PLL1VCOWIDE;
  RCC_OscInitStruct.PLL.PLLFRACN = 0;
  if (HAL_RCC_OscConfig(&RCC_OscInitStruct) != HAL_OK)
  {
    Error_Handler();
  }

  /** Initializes the CPU, AHB and APB buses clocks
  */
  RCC_ClkInitStruct.ClockType = RCC_CLOCKTYPE_HCLK|RCC_CLOCKTYPE_SYSCLK
                              |RCC_CLOCKTYPE_PCLK1|RCC_CLOCKTYPE_PCLK2
                              |RCC_CLOCKTYPE_D3PCLK1|RCC_CLOCKTYPE_D1PCLK1;
  RCC_ClkInitStruct.SYSCLKSource = RCC_SYSCLKSOURCE_PLLCLK;
  RCC_ClkInitStruct.SYSCLKDivider = RCC_SYSCLK_DIV1;
  RCC_ClkInitStruct.AHBCLKDivider = RCC_HCLK_DIV2;
  RCC_ClkInitStruct.APB3CLKDivider = RCC_APB3_DIV2;
  RCC_ClkInitStruct.APB1CLKDivider = RCC_APB1_DIV2;
  RCC_ClkInitStruct.APB2CLKDivider = RCC_APB2_DIV2;
  RCC_ClkInitStruct.APB4CLKDivider = RCC_APB4_DIV2;

  if (HAL_RCC_ClockConfig(&RCC_ClkInitStruct, FLASH_LATENCY_4) != HAL_OK)
  {
    Error_Handler();
  }
}

void PeriphCommonClock_Config(void)
{
  RCC_PeriphCLKInitTypeDef PeriphClkInitStruct = {0};

  /** Initializes the peripherals clock
  */
  PeriphClkInitStruct.PeriphClockSelection = RCC_PERIPHCLK_ADC|RCC_PERIPHCLK_SPI3;
  PeriphClkInitStruct.PLL2.PLL2M = 4;
  PeriphClkInitStruct.PLL2.PLL2N = 9;
  PeriphClkInitStruct.PLL2.PLL2P = 2;
  PeriphClkInitStruct.PLL2.PLL2Q = 2;
  PeriphClkInitStruct.PLL2.PLL2R = 2;
  PeriphClkInitStruct.PLL2.PLL2RGE = RCC_PLL2VCIRANGE_3;
  PeriphClkInitStruct.PLL2.PLL2VCOSEL = RCC_PLL2VCOMEDIUM;
  PeriphClkInitStruct.PLL2.PLL2FRACN = 3072;
  PeriphClkInitStruct.Spi123ClockSelection = RCC_SPI123CLKSOURCE_PLL2;
  PeriphClkInitStruct.AdcClockSelection = RCC_ADCCLKSOURCE_PLL2;
  if (HAL_RCCEx_PeriphCLKConfig(&PeriphClkInitStruct) != HAL_OK)
  {
    Error_Handler();
  }
}

 /* MPU Configuration */

void MPU_Config(void)
{
  MPU_Region_InitTypeDef MPU_InitStruct = {0};

  /* Disables the MPU */
  HAL_MPU_Disable();

  /** Initializes and configures the Region and the memory to be protected
  */
  MPU_InitStruct.Enable = MPU_REGION_ENABLE;
  MPU_InitStruct.Number = MPU_REGION_NUMBER0;
  MPU_InitStruct.BaseAddress = 0x24000000;
  MPU_InitStruct.Size = MPU_REGION_SIZE_4KB;
  MPU_InitStruct.SubRegionDisable = 0x00;
  MPU_InitStruct.TypeExtField = MPU_TEX_LEVEL1;
  MPU_InitStruct.AccessPermission = MPU_REGION_FULL_ACCESS;
  MPU_InitStruct.DisableExec = MPU_INSTRUCTION_ACCESS_DISABLE;
  MPU_InitStruct.IsShareable = MPU_ACCESS_NOT_SHAREABLE;
  MPU_InitStruct.IsCacheable = MPU_ACCESS_NOT_CACHEABLE;
  MPU_InitStruct.IsBufferable = MPU_ACCESS_NOT_BUFFERABLE;

  HAL_MPU_ConfigRegion(&MPU_InitStruct);

  /** Initializes and configures the Region and the memory to be protected
  */
  MPU_InitStruct.Number = MPU_REGION_NUMBER1;
  MPU_InitStruct.Size = MPU_REGION_SIZE_512KB;
  MPU_InitStruct.SubRegionDisable = 0x01;
  MPU_InitStruct.IsCacheable = MPU_ACCESS_CACHEABLE;
  MPU_InitStruct.IsBufferable = MPU_ACCESS_BUFFERABLE;

  HAL_MPU_ConfigRegion(&MPU_InitStruct);
  /* Enables the MPU */
  HAL_MPU_Enable(MPU_PRIVILEGED_DEFAULT);

}

void HAL_TIM_PeriodElapsedCallback(TIM_HandleTypeDef *htim)
{
  if (htim->Instance == TIM17)
  {
    HAL_IncTick();
  }
}

void Error_Handler(void)
{
  __disable_irq();
  while (1)
  {
  }
}

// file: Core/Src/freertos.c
/* USER CODE BEGIN Header */
/**
  ******************************************************************************
  * File Name          : freertos.c
  * Description        : Code for freertos applications
  ******************************************************************************
  * @attention
  *
  * Copyright (c) 2026 STMicroelectronics.
  * All rights reserved.
  *
  * This software is licensed under terms that can be found in the LICENSE file
  * in the root directory of this software component.
  * If no LICENSE file comes with this software, it is provided AS-IS.
  *
  ******************************************************************************
  */
/* USER CODE END Header */

#include "FreeRTOS.h"
#include "task.h"
#include "main.h"
#include "cmsis_os.h"

/* USER CODE BEGIN Includes */
#include "semphr.h"
#include "D:\Downloads\stm32project\mydrone_hal\MDK-ARM\user\driver\uart\uart_base.h"
#include "D:\Downloads\stm32project\mydrone_hal\MDK-ARM\user\user_control\ano\ano_base.h"
QueueHandle_t uart_tx_queue = NULL;
QueueHandle_t uart_rx_queue = NULL;
QueueHandle_t ano_tx_queue = NULL;
extern void syster_timer_init(void);

/* USER CODE END Includes */

/* Definitions for task_1ms_name */
osThreadId_t task_1ms_nameHandle;
const osThreadAttr_t task_1ms_name_attributes = {
  .name = "task_1ms_name",
  .stack_size = 1024 * 4,
  .priority = (osPriority_t) osPriorityHigh,
};
/* Definitions for task_tx_event */
osThreadId_t task_tx_eventHandle;
const osThreadAttr_t task_tx_event_attributes = {
  .name = "task_tx_event",
  .stack_size = 512 * 4,
  .priority = (osPriority_t) osPriorityAboveNormal,
};
/* Definitions for task_rx_event */
osThreadId_t task_rx_eventHandle;
const osThreadAttr_t task_rx_event_attributes = {
  .name = "task_rx_event",
  .stack_size = 512 * 4,
  .priority = (osPriority_t) osPriorityAboveNormal,
};
/* Definitions for task_ano_send_e */
osThreadId_t task_ano_send_eHandle;
const osThreadAttr_t task_ano_send_e_attributes = {
  .name = "task_ano_send_e",
  .stack_size = 512 * 4,
  .priority = (osPriority_t) osPriorityNormal6,
};
/* Definitions for task_event_name */
osThreadId_t task_event_nameHandle;
const osThreadAttr_t task_event_name_attributes = {
  .name = "task_event_name",
  .stack_size = 256 * 4,
  .priority = (osPriority_t) osPriorityNormal7,
};
/* Definitions for task_timer_even */
osThreadId_t task_timer_evenHandle;
const osThreadAttr_t task_timer_even_attributes = {
  .name = "task_timer_even",
  .stack_size = 128 * 4,
  .priority = (osPriority_t) osPriorityAboveNormal1,
};
/* Definitions for task_10ms_name */
osThreadId_t task_10ms_nameHandle;
const osThreadAttr_t task_10ms_name_attributes = {
  .name = "task_10ms_name",
  .stack_size = 512 * 4,
  .priority = (osPriority_t) osPriorityNormal5,
};

void task_1ms(void *argument);
void task_tx(void *argument);
void task_rx(void *argument);
void task_ano_send(void *argument);
void task_event(void *argument);
void task_timer_event(void *argument);
void task_10ms(void *argument);

void MX_FREERTOS_Init(void); /* (MISRA C 2004 rule 8.1) */

/* Hook prototypes */
void configureTimerForRunTimeStats(void);
unsigned long getRunTimeCounterValue(void);

/* USER CODE BEGIN 1 */
/* Functions needed when configGENERATE_RUN_TIME_STATS is on */
__weak void configureTimerForRunTimeStats(void)
{

}

__weak unsigned long getRunTimeCounterValue(void)
{
return 0;
}
/* USER CODE END 1 */

void MX_FREERTOS_Init(void) {

  /* Create the thread(s) */
  /* creation of task_1ms_name */
  task_1ms_nameHandle = osThreadNew(task_1ms, NULL, &task_1ms_name_attributes);

  /* creation of task_tx_event */
  task_tx_eventHandle = osThreadNew(task_tx, NULL, &task_tx_event_attributes);

  /* creation of task_rx_event */
  task_rx_eventHandle = osThreadNew(task_rx, NULL, &task_rx_event_attributes);

  /* creation of task_ano_send_e */
  task_ano_send_eHandle = osThreadNew(task_ano_send, NULL, &task_ano_send_e_attributes);

  /* creation of task_event_name */
  task_event_nameHandle = osThreadNew(task_event, NULL, &task_event_name_attributes);

  /* creation of task_timer_even */
  task_timer_evenHandle = osThreadNew(task_timer_event, NULL, &task_timer_even_attributes);

  /* creation of task_10ms_name */
  task_10ms_nameHandle = osThreadNew(task_10ms, NULL, &task_10ms_name_attributes);

  /* USER CODE BEGIN RTOS_THREADS */
  /* add threads, ... */
    uart_tx_queue = xQueueCreate(30, sizeof(struct uart_event_t));
    uart_rx_queue = xQueueCreate(30, sizeof(struct uart_event_t));
    ano_tx_queue = xQueueCreate(30,sizeof(struct ano_event_t));
  syster_timer_init();
  /* USER CODE END RTOS_THREADS */

}

__weak void task_1ms(void *argument)
{
  for(;;)
  {
    osDelay(1);
  }
}

__weak void task_tx(void *argument)
{
  for(;;)
  {
    osDelay(1);
  }
}

__weak void task_rx(void *argument)
{
  for(;;)
  {
    osDelay(1);
  }
}

__weak void task_ano_send(void *argument)
{
  for(;;)
  {
    osDelay(1);
  }
}

__weak void task_event(void *argument)
{
  for(;;)
  {
    osDelay(1);
  }
}

__weak void task_timer_event(void *argument)
{
  for(;;)
  {
    osDelay(1);
  }
}

__weak void task_10ms(void *argument)
{
  for(;;)
  {
    osDelay(1);
  }
}
